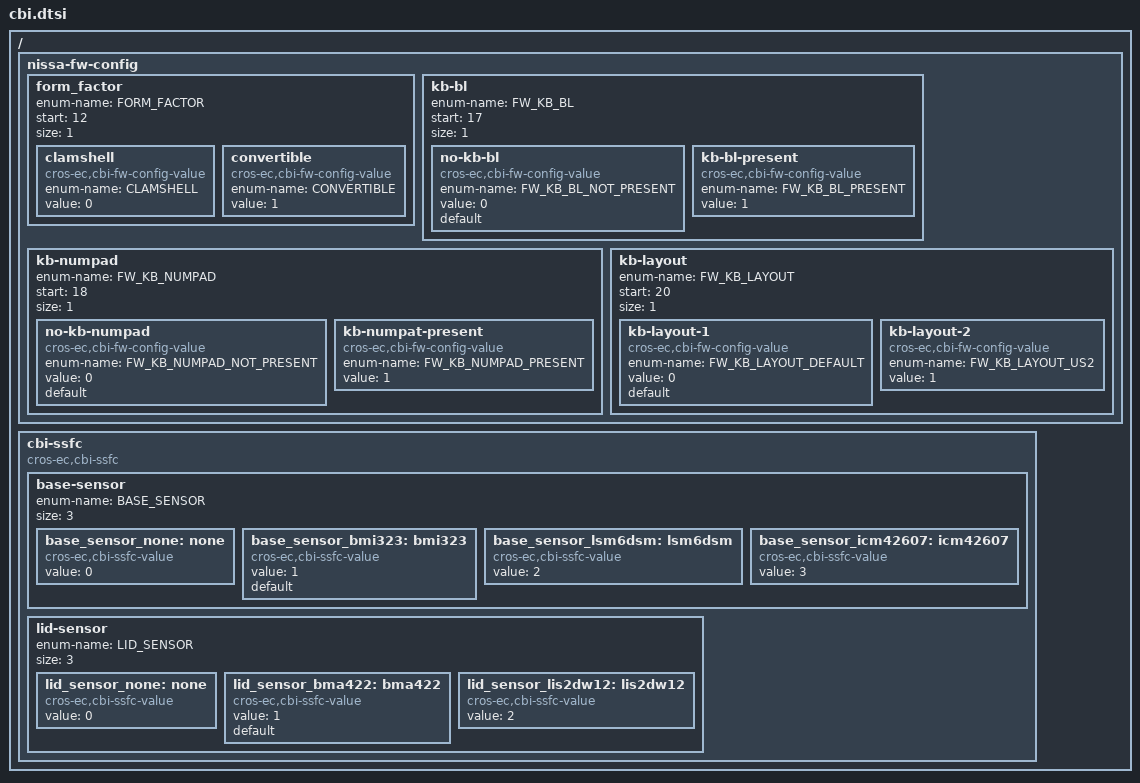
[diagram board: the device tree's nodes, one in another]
/* Copyright 2024 The ChromiumOS Authors
 * Use of this source code is governed by a BSD-style license that can be
 * found in the LICENSE file.
 */

/ {
	/* Telith-specific fw_config fields. */
	nissa-fw-config {
		/*
		 * FW_CONFIG field to describe Clamshell/Convertible.
		 */
		form_factor {
			enum-name = "FORM_FACTOR";
			start = <12>;
			size = <1>;

			/*
			 * 0: clamshell, 1: convertible
			 */
			clamshell {
				compatible = "cros-ec,cbi-fw-config-value";
				enum-name = "CLAMSHELL";
				value = <0>;
			};
			convertible {
				compatible = "cros-ec,cbi-fw-config-value";
				enum-name = "CONVERTIBLE";
				value = <1>;
			};
		};
		/*
		 * FW_CONFIG field to enable KB back light or not.
		 */
		kb-bl {
			enum-name = "FW_KB_BL";
			start = <17>;
			size = <1>;

			no-kb-bl {
				compatible = "cros-ec,cbi-fw-config-value";
				enum-name = "FW_KB_BL_NOT_PRESENT";
				value = <0>;
				default;
			};
			kb-bl-present {
				compatible = "cros-ec,cbi-fw-config-value";
				enum-name = "FW_KB_BL_PRESENT";
				value = <1>;
			};
		};
		/*
		 * FW_CONFIG field to enable KB Numpat or not
		 */
		kb-numpad {
			enum-name = "FW_KB_NUMPAD";
			start = <18>;
			size = <1>;

			no-kb-numpad {
				compatible = "cros-ec,cbi-fw-config-value";
				enum-name = "FW_KB_NUMPAD_NOT_PRESENT";
				value = <0>;
				default;
			};
			kb-numpat-present {
				compatible = "cros-ec,cbi-fw-config-value";
				enum-name = "FW_KB_NUMPAD_PRESENT";
				value = <1>;
			};
		};
		/*
		 * FW_CONFIG field to indicate which keyboard layout
		 * should be used.
		 */
		kb-layout {
			enum-name = "FW_KB_LAYOUT";
			start = <20>;
			size = <1>;

			kb-layout-1 {
				compatible = "cros-ec,cbi-fw-config-value";
				enum-name = "FW_KB_LAYOUT_DEFAULT";
				value = <0>;
				default;
			};
			kb-layout-2 {
				compatible = "cros-ec,cbi-fw-config-value";
				enum-name = "FW_KB_LAYOUT_US2";
				value = <1>;
			};
		};
	};

	/* Telith-specific ssfc fields. */
	cbi-ssfc {
		compatible = "cros-ec,cbi-ssfc";
		/*
		 * SSFC field to identify BASE motion sensor.
		 */
		base-sensor {
			enum-name = "BASE_SENSOR";
			size = <3>;

			base_sensor_none: none {
				compatible = "cros-ec,cbi-ssfc-value";
				status = "okay";
				value = <0>;
			};
			base_sensor_bmi323: bmi323 {
				compatible = "cros-ec,cbi-ssfc-value";
				status = "okay";
				value = <1>;
				default;
			};
			base_sensor_lsm6dsm: lsm6dsm {
				compatible = "cros-ec,cbi-ssfc-value";
				status = "okay";
				value = <2>;
			};
			base_sensor_icm42607: icm42607 {
				compatible = "cros-ec,cbi-ssfc-value";
				status = "okay";
				value = <3>;
			};
		};

		/* SSFC field to identify LID motion sensor. */
		lid-sensor {
			enum-name = "LID_SENSOR";
			size = <3>;

			lid_sensor_none: none {
				compatible = "cros-ec,cbi-ssfc-value";
				status = "okay";
				value = <0>;
			};
			lid_sensor_bma422: bma422 {
				compatible = "cros-ec,cbi-ssfc-value";
				status = "okay";
				value = <1>;
				default;
			};
			lid_sensor_lis2dw12: lis2dw12 {
				compatible = "cros-ec,cbi-ssfc-value";
				status = "okay";
				value = <2>;
			};
		};
	};
};
